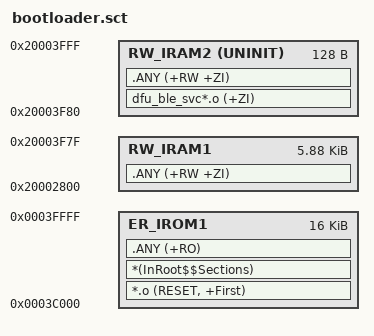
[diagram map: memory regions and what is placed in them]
LR_IROM1 0x0003C000 0x00004000  {    ; load region size_region
  ER_IROM1 0x0003C000 0x00004000  {  ; load address = execution address
   *.o (RESET, +First)
   *(InRoot$$Sections)
   .ANY (+RO)
  }
  RW_IRAM1 0x20002800 0x00001780  {  ; RW data
   .ANY (+RW +ZI)
  }
  RW_IRAM2 0x20003F80 UNINIT 0x00000080  {
    dfu_ble_svc*.o (+ZI)
   .ANY (+RW +ZI)
  }
}
